# AVR32DD20 register map
Vendor: Atmel; File version: 1.0
CPU: other r0p0, little endian, no MPU, no FPU, 4 interrupt priority bits
Registers are 8-bit, read-write, reset 0x0 unless marked. A register's access mark holds for its fields unless they carry their own. Offsets are from the block's base; [hi:lo] are bit positions; {n}, {i} and the like mark numbered series; 'fields as' and 'values as' point back to an identical list.

## PORTA — I/O Ports
Base 0x00000400
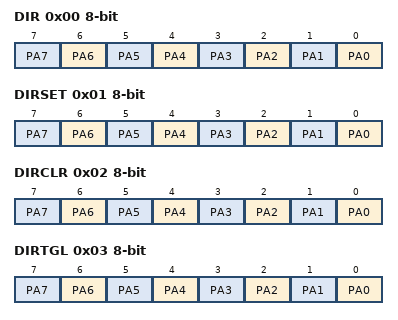
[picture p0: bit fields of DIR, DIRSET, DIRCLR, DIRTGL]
0x00 DIR — Data Direction
  [n] PA{n} (n=0..7) — Pin A{n}
0x01 DIRSET — Data Direction Set
  [n] PA{n} (n=0..7) — Pin A{n}
0x02 DIRCLR — Data Direction Clear
  [n] PA{n} (n=0..7) — Pin A{n}
0x03 DIRTGL — Data Direction Toggle
  [n] PA{n} (n=0..7) — Pin A{n}
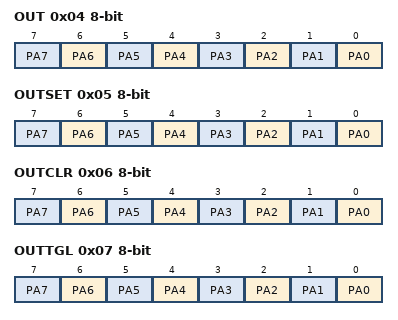
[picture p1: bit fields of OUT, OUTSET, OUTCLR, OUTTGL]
0x04 OUT — Output Value
  [n] PA{n} (n=0..7) — Pin A{n}
0x05 OUTSET — Output Value Set
  [n] PA{n} (n=0..7) — Pin A{n}
0x06 OUTCLR — Output Value Clear
  [n] PA{n} (n=0..7) — Pin A{n}
0x07 OUTTGL — Output Value Toggle
  [n] PA{n} (n=0..7) — Pin A{n}
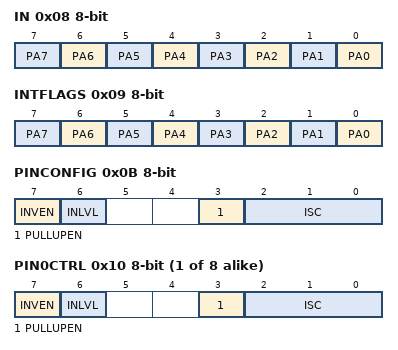
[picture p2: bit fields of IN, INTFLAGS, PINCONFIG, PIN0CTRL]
0x08 IN — Input Value
  [n] PA{n} (n=0..7) — Pin A{n}
0x09 INTFLAGS — Interrupt Flags
  [n] PA{n} (n=0..7) — Pin A{n}
0x0A PORTCTRL — Port Control
  [0] SRL — Slew Rate Limit Enable
0x0B PINCONFIG — Pin Control Config
  [7] INVEN — Inverted I/O Enable
  [6] INLVL — Input level select
  [3] PULLUPEN — Pullup enable
  [2:0] ISC — Input/Sense Configuration
    0=INTDISABLE (Interrupt disabled but input buffer enabled); 1=BOTHEDGES (Sense Both Edges); 2=RISING (Sense Rising Edge); 3=FALLING (Sense Falling Edge); 4=INPUT_DISABLE (Digital Input Buffer disabled); 5=LEVEL (Sense low Level)
0x0C PINCTRLUPD — Pin Control Update
  [7:0] PINCTRLUPD — Pin control update mask
0x0D PINCTRLSET — Pin Control Set
  [7:0] PINCTRLSET — Pin control set mask
0x0E PINCTRLCLR — Pin Control Clear
  [7:0] PINCTRLCLR — Pin control clear mask
{0x10+i} PIN{i}CTRL (i=0..7) — Pin {i} Control
  fields as PINCONFIG

## PORTC — I/O Ports
Base 0x00000440
Registers as PORTA, without PORTCTRL; these are added or differ:
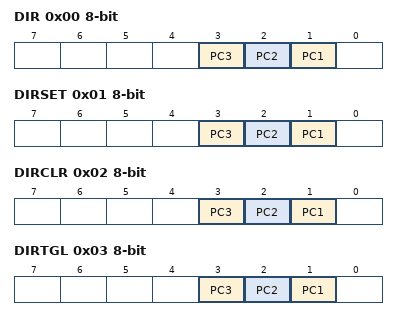
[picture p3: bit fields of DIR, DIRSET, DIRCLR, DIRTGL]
0x00 DIR — Data Direction
  [3] PC3 — Pin C3
  [2] PC2 — Pin C2
  [1] PC1 — Pin C1
0x01 DIRSET — Data Direction Set
  [3] PC3 — Pin C3
  [2] PC2 — Pin C2
  [1] PC1 — Pin C1
0x02 DIRCLR — Data Direction Clear
  [3] PC3 — Pin C3
  [2] PC2 — Pin C2
  [1] PC1 — Pin C1
0x03 DIRTGL — Data Direction Toggle
  [3] PC3 — Pin C3
  [2] PC2 — Pin C2
  [1] PC1 — Pin C1
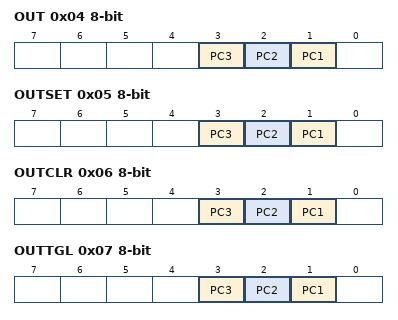
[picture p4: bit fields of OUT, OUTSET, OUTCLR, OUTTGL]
0x04 OUT — Output Value
  [3] PC3 — Pin C3
  [2] PC2 — Pin C2
  [1] PC1 — Pin C1
0x05 OUTSET — Output Value Set
  [3] PC3 — Pin C3
  [2] PC2 — Pin C2
  [1] PC1 — Pin C1
0x06 OUTCLR — Output Value Clear
  [3] PC3 — Pin C3
  [2] PC2 — Pin C2
  [1] PC1 — Pin C1
0x07 OUTTGL — Output Value Toggle
  [3] PC3 — Pin C3
  [2] PC2 — Pin C2
  [1] PC1 — Pin C1
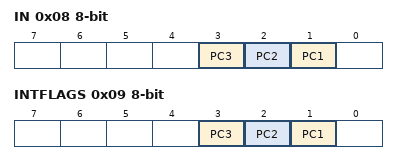
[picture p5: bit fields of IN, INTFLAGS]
0x08 IN — Input Value
  [3] PC3 — Pin C3
  [2] PC2 — Pin C2
  [1] PC1 — Pin C1
0x09 INTFLAGS — Interrupt Flags
  [3] PC3 — Pin C3
  [2] PC2 — Pin C2
  [1] PC1 — Pin C1
0x0A PORTCTRL — Port Control
  [0] SRL — Slew Rate Limit Enable

## PORTD — I/O Ports
Base 0x00000460
Registers as PORTA; these are added or differ:
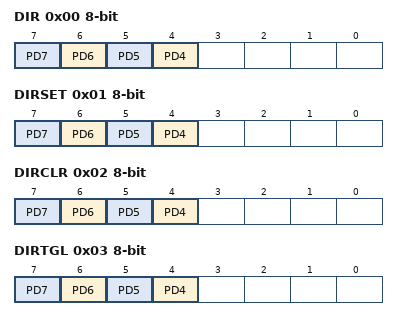
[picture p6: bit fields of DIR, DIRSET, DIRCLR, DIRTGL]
0x00 DIR — Data Direction
  [n] PD{n} (n=4..7) — Pin D{n}
0x01 DIRSET — Data Direction Set
  [n] PD{n} (n=4..7) — Pin D{n}
0x02 DIRCLR — Data Direction Clear
  [n] PD{n} (n=4..7) — Pin D{n}
0x03 DIRTGL — Data Direction Toggle
  [n] PD{n} (n=4..7) — Pin D{n}
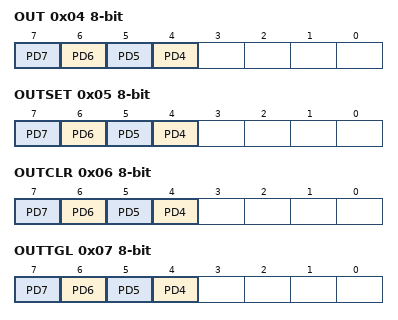
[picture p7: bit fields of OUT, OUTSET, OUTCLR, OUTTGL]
0x04 OUT — Output Value
  [n] PD{n} (n=4..7) — Pin D{n}
0x05 OUTSET — Output Value Set
  [n] PD{n} (n=4..7) — Pin D{n}
0x06 OUTCLR — Output Value Clear
  [n] PD{n} (n=4..7) — Pin D{n}
0x07 OUTTGL — Output Value Toggle
  [n] PD{n} (n=4..7) — Pin D{n}
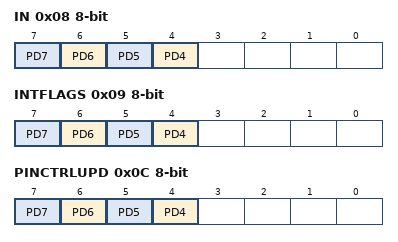
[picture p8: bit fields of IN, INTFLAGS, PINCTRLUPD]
0x08 IN — Input Value
  [n] PD{n} (n=4..7) — Pin D{n}
0x09 INTFLAGS — Interrupt Flags
  [n] PD{n} (n=4..7) — Pin D{n}
0x0C PINCTRLUPD — Pin Control Update
  [n] PD{n} (n=4..7) — Pin D{n}

## PORTF — I/O Ports
Base 0x000004A0
Registers as PORTA; these are added or differ:
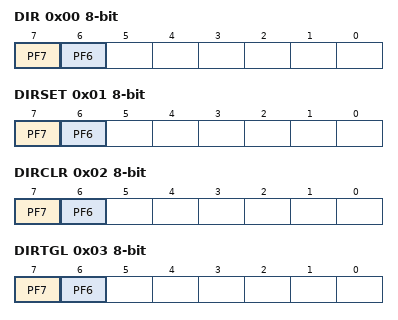
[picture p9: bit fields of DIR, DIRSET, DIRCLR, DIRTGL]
0x00 DIR — Data Direction
  [7] PF7 — Pin F7
  [6] PF6 — Pin F6
0x01 DIRSET — Data Direction Set
  [7] PF7 — Pin F7
  [6] PF6 — Pin F6
0x02 DIRCLR — Data Direction Clear
  [7] PF7 — Pin F7
  [6] PF6 — Pin F6
0x03 DIRTGL — Data Direction Toggle
  [7] PF7 — Pin F7
  [6] PF6 — Pin F6
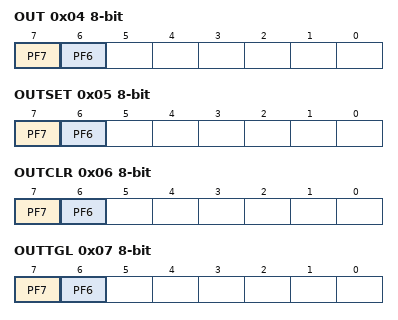
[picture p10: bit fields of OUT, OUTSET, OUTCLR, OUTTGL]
0x04 OUT — Output Value
  [7] PF7 — Pin F7
  [6] PF6 — Pin F6
0x05 OUTSET — Output Value Set
  [7] PF7 — Pin F7
  [6] PF6 — Pin F6
0x06 OUTCLR — Output Value Clear
  [7] PF7 — Pin F7
  [6] PF6 — Pin F6
0x07 OUTTGL — Output Value Toggle
  [7] PF7 — Pin F7
  [6] PF6 — Pin F6
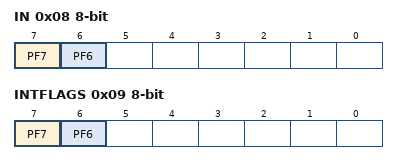
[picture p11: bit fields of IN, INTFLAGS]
0x08 IN — Input Value
  [7] PF7 — Pin F7
  [6] PF6 — Pin F6
0x09 INTFLAGS — Interrupt Flags
  [7] PF7 — Pin F7
  [6] PF6 — Pin F6
